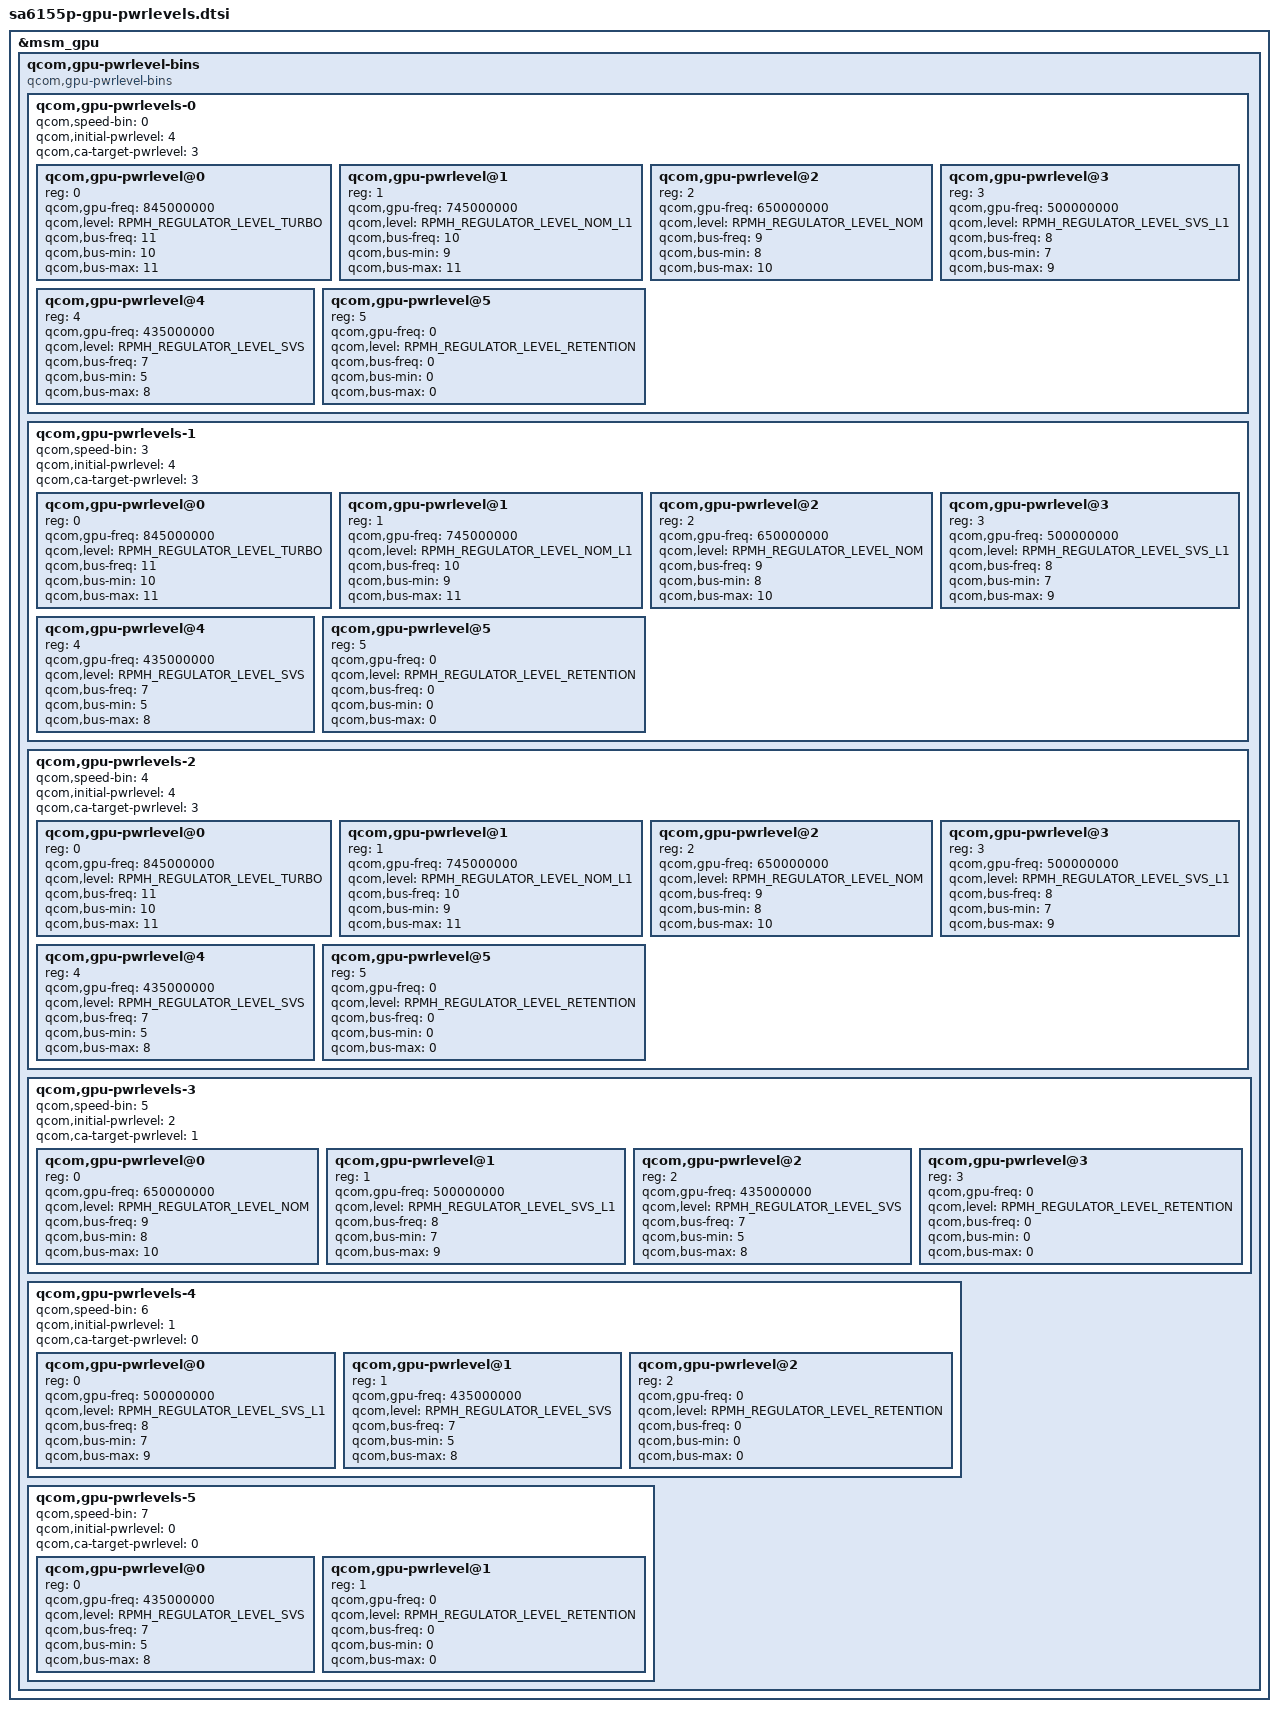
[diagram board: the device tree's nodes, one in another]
/* GPU Powerlevel overrides for SA6155p */
&msm_gpu {
	qcom,gpu-pwrlevel-bins {
		#address-cells = <1>;
		#size-cells = <0>;

		compatible="qcom,gpu-pwrlevel-bins";

		qcom,gpu-pwrlevels-0 {
			#address-cells = <1>;
			#size-cells = <0>;

			qcom,speed-bin = <0>;

			qcom,initial-pwrlevel = <4>;
			qcom,ca-target-pwrlevel = <3>;

			/* TURBO */
			qcom,gpu-pwrlevel@0 {
				reg = <0>;
				qcom,gpu-freq = <845000000>;
				qcom,level = <RPMH_REGULATOR_LEVEL_TURBO>;
				qcom,bus-freq = <11>;
				qcom,bus-min = <10>;
				qcom,bus-max = <11>;
			};

			/* NOM L1 */
			qcom,gpu-pwrlevel@1 {
				reg = <1>;
				qcom,gpu-freq = <745000000>;
				qcom,level = <RPMH_REGULATOR_LEVEL_NOM_L1>;
				qcom,bus-freq = <10>;
				qcom,bus-min = <9>;
				qcom,bus-max = <11>;
			};

			/* NOM */
			qcom,gpu-pwrlevel@2 {
				reg = <2>;
				qcom,gpu-freq = <650000000>;
				qcom,level = <RPMH_REGULATOR_LEVEL_NOM>;
				qcom,bus-freq = <9>;
				qcom,bus-min = <8>;
				qcom,bus-max = <10>;
			};

			/* SVS L1 */
			qcom,gpu-pwrlevel@3 {
				reg = <3>;
				qcom,gpu-freq = <500000000>;
				qcom,level = <RPMH_REGULATOR_LEVEL_SVS_L1>;
				qcom,bus-freq = <8>;
				qcom,bus-min = <7>;
				qcom,bus-max = <9>;
			};

			/* SVS */
			qcom,gpu-pwrlevel@4 {
				reg = <4>;
				qcom,gpu-freq = <435000000>;
				qcom,level = <RPMH_REGULATOR_LEVEL_SVS>;
				qcom,bus-freq = <7>;
				qcom,bus-min = <5>;
				qcom,bus-max = <8>;
			};

			/* XO */
			qcom,gpu-pwrlevel@5 {
				reg = <5>;
				qcom,gpu-freq = <0>;
				qcom,level = <RPMH_REGULATOR_LEVEL_RETENTION>;
				qcom,bus-freq = <0>;
				qcom,bus-min = <0>;
				qcom,bus-max = <0>;
			};
		};

		qcom,gpu-pwrlevels-1 {
			#address-cells = <1>;
			#size-cells = <0>;

			qcom,speed-bin = <3>;

			qcom,initial-pwrlevel = <4>;
			qcom,ca-target-pwrlevel = <3>;

			/* TURBO */
			qcom,gpu-pwrlevel@0 {
				reg = <0>;
				qcom,gpu-freq = <845000000>;
				qcom,level = <RPMH_REGULATOR_LEVEL_TURBO>;
				qcom,bus-freq = <11>;
				qcom,bus-min = <10>;
				qcom,bus-max = <11>;
			};

			/* NOM L1 */
			qcom,gpu-pwrlevel@1 {
				reg = <1>;
				qcom,gpu-freq = <745000000>;
				qcom,level = <RPMH_REGULATOR_LEVEL_NOM_L1>;
				qcom,bus-freq = <10>;
				qcom,bus-min = <9>;
				qcom,bus-max = <11>;
			};

			/* NOM */
			qcom,gpu-pwrlevel@2 {
				reg = <2>;
				qcom,gpu-freq = <650000000>;
				qcom,level = <RPMH_REGULATOR_LEVEL_NOM>;
				qcom,bus-freq = <9>;
				qcom,bus-min = <8>;
				qcom,bus-max = <10>;
			};

			/* SVS L1 */
			qcom,gpu-pwrlevel@3 {
				reg = <3>;
				qcom,gpu-freq = <500000000>;
				qcom,level = <RPMH_REGULATOR_LEVEL_SVS_L1>;
				qcom,bus-freq = <8>;
				qcom,bus-min = <7>;
				qcom,bus-max = <9>;
			};

			/* SVS */
			qcom,gpu-pwrlevel@4 {
				reg = <4>;
				qcom,gpu-freq = <435000000>;
				qcom,level = <RPMH_REGULATOR_LEVEL_SVS>;
				qcom,bus-freq = <7>;
				qcom,bus-min = <5>;
				qcom,bus-max = <8>;
			};

			/* XO */
			qcom,gpu-pwrlevel@5 {
				reg = <5>;
				qcom,gpu-freq = <0>;
				qcom,level = <RPMH_REGULATOR_LEVEL_RETENTION>;
				qcom,bus-freq = <0>;
				qcom,bus-min = <0>;
				qcom,bus-max = <0>;
			};
		};

		qcom,gpu-pwrlevels-2 {
			#address-cells = <1>;
			#size-cells = <0>;

			qcom,speed-bin = <4>;

			qcom,initial-pwrlevel = <4>;
			qcom,ca-target-pwrlevel = <3>;

			/* TURBO */
			qcom,gpu-pwrlevel@0 {
				reg = <0>;
				qcom,gpu-freq = <845000000>;
				qcom,level = <RPMH_REGULATOR_LEVEL_TURBO>;
				qcom,bus-freq = <11>;
				qcom,bus-min = <10>;
				qcom,bus-max = <11>;
			};

			/* NOM L1 */
			qcom,gpu-pwrlevel@1 {
				reg = <1>;
				qcom,gpu-freq = <745000000>;
				qcom,level = <RPMH_REGULATOR_LEVEL_NOM_L1>;
				qcom,bus-freq = <10>;
				qcom,bus-min = <9>;
				qcom,bus-max = <11>;
			};

			/* NOM */
			qcom,gpu-pwrlevel@2 {
				reg = <2>;
				qcom,gpu-freq = <650000000>;
				qcom,level = <RPMH_REGULATOR_LEVEL_NOM>;
				qcom,bus-freq = <9>;
				qcom,bus-min = <8>;
				qcom,bus-max = <10>;
			};

			/* SVS L1 */
			qcom,gpu-pwrlevel@3 {
				reg = <3>;
				qcom,gpu-freq = <500000000>;
				qcom,level = <RPMH_REGULATOR_LEVEL_SVS_L1>;
				qcom,bus-freq = <8>;
				qcom,bus-min = <7>;
				qcom,bus-max = <9>;
			};

			/* SVS */
			qcom,gpu-pwrlevel@4 {
				reg = <4>;
				qcom,gpu-freq = <435000000>;
				qcom,level = <RPMH_REGULATOR_LEVEL_SVS>;
				qcom,bus-freq = <7>;
				qcom,bus-min = <5>;
				qcom,bus-max = <8>;
			};

			/* XO */
			qcom,gpu-pwrlevel@5 {
				reg = <5>;
				qcom,gpu-freq = <0>;
				qcom,level = <RPMH_REGULATOR_LEVEL_RETENTION>;
				qcom,bus-freq = <0>;
				qcom,bus-min = <0>;
				qcom,bus-max = <0>;
			};
		};

		qcom,gpu-pwrlevels-3 {
			#address-cells = <1>;
			#size-cells = <0>;

			qcom,speed-bin = <5>;

			qcom,initial-pwrlevel = <2>;
			qcom,ca-target-pwrlevel = <1>;

			/* NOM */
			qcom,gpu-pwrlevel@0 {
				reg = <0>;
				qcom,gpu-freq = <650000000>;
				qcom,level = <RPMH_REGULATOR_LEVEL_NOM>;
				qcom,bus-freq = <9>;
				qcom,bus-min = <8>;
				qcom,bus-max = <10>;
			};

			/* SVS L1 */
			qcom,gpu-pwrlevel@1 {
				reg = <1>;
				qcom,gpu-freq = <500000000>;
				qcom,level = <RPMH_REGULATOR_LEVEL_SVS_L1>;
				qcom,bus-freq = <8>;
				qcom,bus-min = <7>;
				qcom,bus-max = <9>;
			};

			/* SVS */
			qcom,gpu-pwrlevel@2 {
				reg = <2>;
				qcom,gpu-freq = <435000000>;
				qcom,level = <RPMH_REGULATOR_LEVEL_SVS>;
				qcom,bus-freq = <7>;
				qcom,bus-min = <5>;
				qcom,bus-max = <8>;
			};

			/* XO */
			qcom,gpu-pwrlevel@3 {
				reg = <3>;
				qcom,gpu-freq = <0>;
				qcom,level = <RPMH_REGULATOR_LEVEL_RETENTION>;
				qcom,bus-freq = <0>;
				qcom,bus-min = <0>;
				qcom,bus-max = <0>;
			};
		};

		qcom,gpu-pwrlevels-4 {
			#address-cells = <1>;
			#size-cells = <0>;

			qcom,speed-bin = <6>;

			qcom,initial-pwrlevel = <1>;
			qcom,ca-target-pwrlevel = <0>;

			/* SVS L1 */
			qcom,gpu-pwrlevel@0 {
				reg = <0>;
				qcom,gpu-freq = <500000000>;
				qcom,level = <RPMH_REGULATOR_LEVEL_SVS_L1>;
				qcom,bus-freq = <8>;
				qcom,bus-min = <7>;
				qcom,bus-max = <9>;
			};

			/* SVS */
			qcom,gpu-pwrlevel@1 {
				reg = <1>;
				qcom,gpu-freq = <435000000>;
				qcom,level = <RPMH_REGULATOR_LEVEL_SVS>;
				qcom,bus-freq = <7>;
				qcom,bus-min = <5>;
				qcom,bus-max = <8>;
			};

			/* XO */
			qcom,gpu-pwrlevel@2 {
				reg = <2>;
				qcom,gpu-freq = <0>;
				qcom,level = <RPMH_REGULATOR_LEVEL_RETENTION>;
				qcom,bus-freq = <0>;
				qcom,bus-min = <0>;
				qcom,bus-max = <0>;
			};
		};

		qcom,gpu-pwrlevels-5 {
			#address-cells = <1>;
			#size-cells = <0>;

			qcom,speed-bin = <7>;

			qcom,initial-pwrlevel = <0>;
			qcom,ca-target-pwrlevel = <0>;

			/* SVS */
			qcom,gpu-pwrlevel@0 {
				reg = <0>;
				qcom,gpu-freq = <435000000>;
				qcom,level = <RPMH_REGULATOR_LEVEL_SVS>;
				qcom,bus-freq = <7>;
				qcom,bus-min = <5>;
				qcom,bus-max = <8>;
			};

			/* XO */
			qcom,gpu-pwrlevel@1 {
				reg = <1>;
				qcom,gpu-freq = <0>;
				qcom,level = <RPMH_REGULATOR_LEVEL_RETENTION>;
				qcom,bus-freq = <0>;
				qcom,bus-min = <0>;
				qcom,bus-max = <0>;
			};
		};
	};
};
